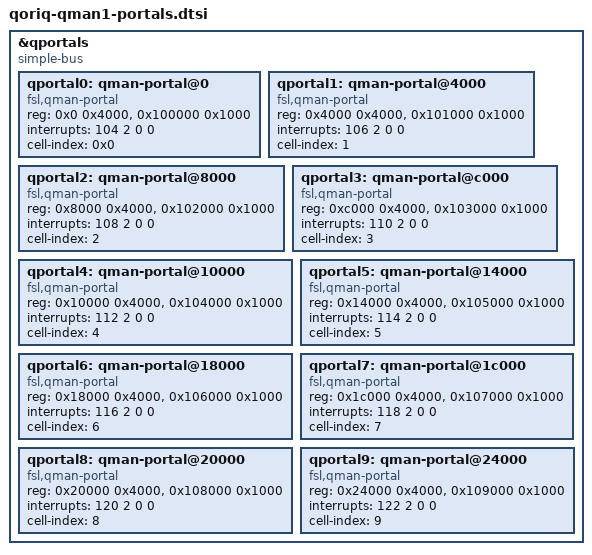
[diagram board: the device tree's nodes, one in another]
/*
 * QorIQ QMan Portal device tree stub for 10 portals & 15 pool channels
 *
 * Copyright 2011 - 2014 Freescale Semiconductor Inc.
 *
 * Redistribution and use in source and binary forms, with or without
 * modification, are permitted provided that the following conditions are met:
 *     * Redistributions of source code must retain the above copyright
 *	 notice, this list of conditions and the following disclaimer.
 *     * Redistributions in binary form must reproduce the above copyright
 *	 notice, this list of conditions and the following disclaimer in the
 *	 documentation and/or other materials provided with the distribution.
 *     * Neither the name of Freescale Semiconductor nor the
 *	 names of its contributors may be used to endorse or promote products
 *	 derived from this software without specific prior written permission.
 *
 *
 * ALTERNATIVELY, this software may be distributed under the terms of the
 * GNU General Public License ("GPL") as published by the Free Software
 * Foundation, either version 2 of that License or (at your option) any
 * later version.
 *
 * THIS SOFTWARE IS PROVIDED BY Freescale Semiconductor ``AS IS'' AND ANY
 * EXPRESS OR IMPLIED WARRANTIES, INCLUDING, BUT NOT LIMITED TO, THE IMPLIED
 * WARRANTIES OF MERCHANTABILITY AND FITNESS FOR A PARTICULAR PURPOSE ARE
 * DISCLAIMED. IN NO EVENT SHALL Freescale Semiconductor BE LIABLE FOR ANY
 * DIRECT, INDIRECT, INCIDENTAL, SPECIAL, EXEMPLARY, OR CONSEQUENTIAL DAMAGES
 * (INCLUDING, BUT NOT LIMITED TO, PROCUREMENT OF SUBSTITUTE GOODS OR SERVICES;
 * LOSS OF USE, DATA, OR PROFITS; OR BUSINESS INTERRUPTION) HOWEVER CAUSED AND
 * ON ANY THEORY OF LIABILITY, WHETHER IN CONTRACT, STRICT LIABILITY, OR TORT
 * (INCLUDING NEGLIGENCE OR OTHERWISE) ARISING IN ANY WAY OUT OF THE USE OF THIS
 * SOFTWARE, EVEN IF ADVISED OF THE POSSIBILITY OF SUCH DAMAGE.
 */

&qportals {
	#address-cells = <1>;
	#size-cells = <1>;
	compatible = "simple-bus";

	qportal0: qman-portal@0 {
		compatible = "fsl,qman-portal";
		reg = <0x0 0x4000>, <0x100000 0x1000>;
		interrupts = <104 2 0 0>;
		cell-index = <0x0>;
	};
	qportal1: qman-portal@4000 {
		compatible = "fsl,qman-portal";
		reg = <0x4000 0x4000>, <0x101000 0x1000>;
		interrupts = <106 2 0 0>;
		cell-index = <1>;
	};
	qportal2: qman-portal@8000 {
		compatible = "fsl,qman-portal";
		reg = <0x8000 0x4000>, <0x102000 0x1000>;
		interrupts = <108 2 0 0>;
		cell-index = <2>;
	};
	qportal3: qman-portal@c000 {
		compatible = "fsl,qman-portal";
		reg = <0xc000 0x4000>, <0x103000 0x1000>;
		interrupts = <110 2 0 0>;
		cell-index = <3>;
	};
	qportal4: qman-portal@10000 {
		compatible = "fsl,qman-portal";
		reg = <0x10000 0x4000>, <0x104000 0x1000>;
		interrupts = <112 2 0 0>;
		cell-index = <4>;
	};
	qportal5: qman-portal@14000 {
		compatible = "fsl,qman-portal";
		reg = <0x14000 0x4000>, <0x105000 0x1000>;
		interrupts = <114 2 0 0>;
		cell-index = <5>;
	};
	qportal6: qman-portal@18000 {
		compatible = "fsl,qman-portal";
		reg = <0x18000 0x4000>, <0x106000 0x1000>;
		interrupts = <116 2 0 0>;
		cell-index = <6>;
	};

	qportal7: qman-portal@1c000 {
		compatible = "fsl,qman-portal";
		reg = <0x1c000 0x4000>, <0x107000 0x1000>;
		interrupts = <118 2 0 0>;
		cell-index = <7>;
	};
	qportal8: qman-portal@20000 {
		compatible = "fsl,qman-portal";
		reg = <0x20000 0x4000>, <0x108000 0x1000>;
		interrupts = <120 2 0 0>;
		cell-index = <8>;
	};
	qportal9: qman-portal@24000 {
		compatible = "fsl,qman-portal";
		reg = <0x24000 0x4000>, <0x109000 0x1000>;
		interrupts = <122 2 0 0>;
		cell-index = <9>;
	};
};
